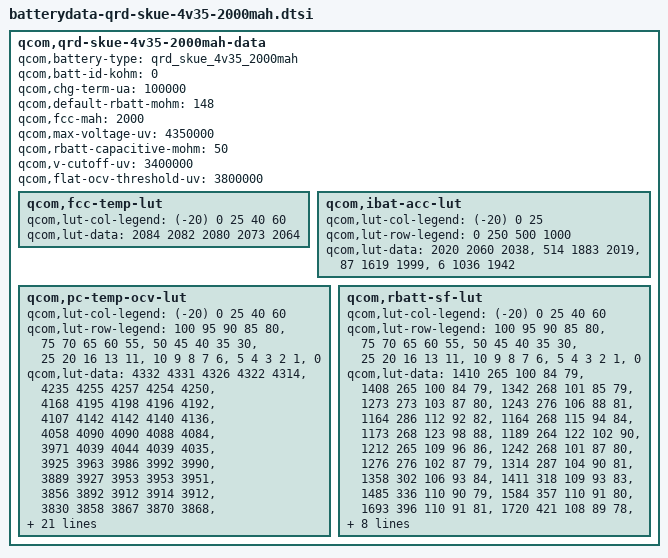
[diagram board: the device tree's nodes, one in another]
/* Copyright (c) 2017, The Linux Foundation. All rights reserved.
 *
 * This program is free software; you can redistribute it and/or modify
 * it under the terms of the GNU General Public License version 2 and
 * only version 2 as published by the Free Software Foundation.
 *
 * This program is distributed in the hope that it will be useful,
 * but WITHOUT ANY WARRANTY; without even the implied warranty of
 * MERCHANTABILITY or FITNESS FOR A PARTICULAR PURPOSE.  See the
 * GNU General Public License for more details.
 */

qcom,qrd-skue-4v35-2000mah-data {
	qcom,battery-type = "qrd_skue_4v35_2000mah";
	qcom,batt-id-kohm = <0>;
	qcom,chg-term-ua = <100000>;
	qcom,default-rbatt-mohm = <148>;
	qcom,fcc-mah = <2000>;
	qcom,max-voltage-uv = <4350000>;
	qcom,rbatt-capacitive-mohm = <50>;
	qcom,v-cutoff-uv = <3400000>;
	qcom,flat-ocv-threshold-uv = <3800000>;

	qcom,fcc-temp-lut {
		qcom,lut-col-legend = <(-20) 0 25 40 60>;
		qcom,lut-data = <2084 2082 2080 2073 2064>;
	};

	qcom,ibat-acc-lut {
		qcom,lut-col-legend = <(-20) 0 25>;
		qcom,lut-row-legend = <0 250 500 1000>;
		qcom,lut-data = <2020 2060 2038>,
				<514 1883 2019>,
				<87 1619 1999>,
				<6 1036 1942>;
	};

	qcom,pc-temp-ocv-lut {
		qcom,lut-col-legend = <(-20) 0 25 40 60>;
		qcom,lut-row-legend = <100 95 90 85 80>,
					<75 70 65 60 55>,
					<50 45 40 35 30>,
					<25 20 16 13 11>,
					<10 9 8 7 6>,
					<5 4 3 2 1>,
					<0>;
		qcom,lut-data = <4332 4331 4326 4322 4314>,
				<4235 4255 4257 4254 4250>,
				<4168 4195 4198 4196 4192>,
				<4107 4142 4142 4140 4136>,
				<4058 4090 4090 4088 4084>,
				<3971 4039 4044 4039 4035>,
				<3925 3963 3986 3992 3990>,
				<3889 3927 3953 3953 3951>,
				<3856 3892 3912 3914 3912>,
				<3830 3858 3867 3870 3868>,
				<3808 3829 3834 3835 3833>,
				<3790 3806 3811 3811 3810>,
				<3775 3788 3793 3794 3792>,
				<3760 3775 3780 3779 3778>,
				<3746 3764 3769 3765 3758>,
				<3730 3749 3757 3749 3735>,
				<3711 3730 3739 3730 3715>,
				<3693 3715 3715 3708 3693>,
				<3674 3706 3692 3684 3671>,
				<3656 3699 3688 3679 3668>,
				<3646 3695 3686 3678 3667>,
				<3633 3692 3685 3677 3666>,
				<3617 3686 3683 3676 3664>,
				<3597 3680 3680 3673 3661>,
				<3573 3667 3672 3665 3651>,
				<3542 3643 3647 3641 3622>,
				<3500 3603 3602 3598 3577>,
				<3440 3545 3540 3539 3520>,
				<3347 3463 3458 3463 3434>,
				<3189 3340 3337 3345 3302>,
				<3000 3106 3000 3000 3000>;
	};

	qcom,rbatt-sf-lut {
		qcom,lut-col-legend = <(-20) 0 25 40 60>;
		qcom,lut-row-legend = <100 95 90 85 80>,
					<75 70 65 60 55>,
					<50 45 40 35 30>,
					<25 20 16 13 11>,
					<10 9 8 7 6>,
					<5 4 3 2 1>,
					<0>;
		qcom,lut-data = <1410 265 100 84 79>,
				<1408 265 100 84 79>,
				<1342 268 101 85 79>,
				<1273 273 103 87 80>,
				<1243 276 106 88 81>,
				<1164 286 112 92 82>,
				<1164 268 115 94 84>,
				<1173 268 123 98 88>,
				<1189 264 122 102 90>,
				<1212 265 109 96 86>,
				<1242 268 101 87 80>,
				<1276 276 102 87 79>,
				<1314 287 104 90 81>,
				<1358 302 106 93 84>,
				<1411 318 109 93 83>,
				<1485 336 110 90 79>,
				<1584 357 110 91 80>,
				<1693 396 110 91 81>,
				<1720 421 108 89 78>,
				<1960 465 110 89 80>,
				<2175 494 112 91 81>,
				<2445 530 114 94 83>,
				<2825 573 119 96 86>,
				<3334 629 125 99 89>,
				<4062 689 130 100 89>,
				<5168 783 129 99 83>,
				<6923 916 132 99 85>,
				<10172 1160 145 105 90>,
				<16692 1530 169 119 103>,
				<104534 2708 230 145 150>,
				<279842 43438 178115 106625 131239>;
	};
};
